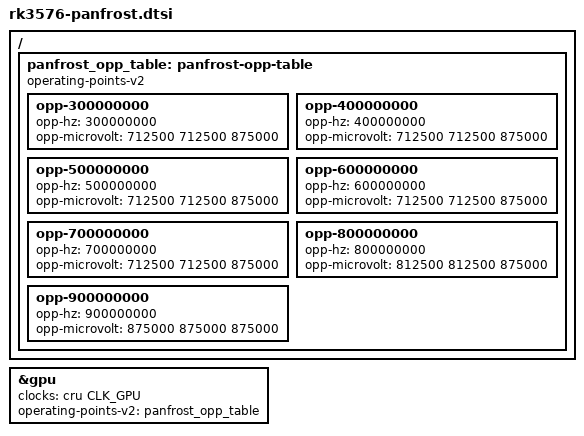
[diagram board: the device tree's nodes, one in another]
// SPDX-License-Identifier: (GPL-2.0+ OR MIT)
/*
 * Copyright (c) 2025 Radxa Computer (Shenzhen) Co., Ltd.
 */

/ {
	/* Standard RK3576 OPPs for Panfrost, which does not select BSP speed bins. */
	panfrost_opp_table: panfrost-opp-table {
		compatible = "operating-points-v2";

		opp-300000000 {
			opp-hz = /bits/ 64 <300000000>;
			opp-microvolt = <712500 712500 875000>;
		};
		opp-400000000 {
			opp-hz = /bits/ 64 <400000000>;
			opp-microvolt = <712500 712500 875000>;
		};
		opp-500000000 {
			opp-hz = /bits/ 64 <500000000>;
			opp-microvolt = <712500 712500 875000>;
		};
		opp-600000000 {
			opp-hz = /bits/ 64 <600000000>;
			opp-microvolt = <712500 712500 875000>;
		};
		opp-700000000 {
			opp-hz = /bits/ 64 <700000000>;
			opp-microvolt = <712500 712500 875000>;
		};
		opp-800000000 {
			opp-hz = /bits/ 64 <800000000>;
			opp-microvolt = <812500 812500 875000>;
		};
		opp-900000000 {
			opp-hz = /bits/ 64 <900000000>;
			opp-microvolt = <875000 875000 875000>;
		};
	};
};

&gpu {
	interrupt-names = "gpu", "mmu", "job";
	clocks = <&cru CLK_GPU>;
	clock-names = "core";
	operating-points-v2 = <&panfrost_opp_table>;
};
